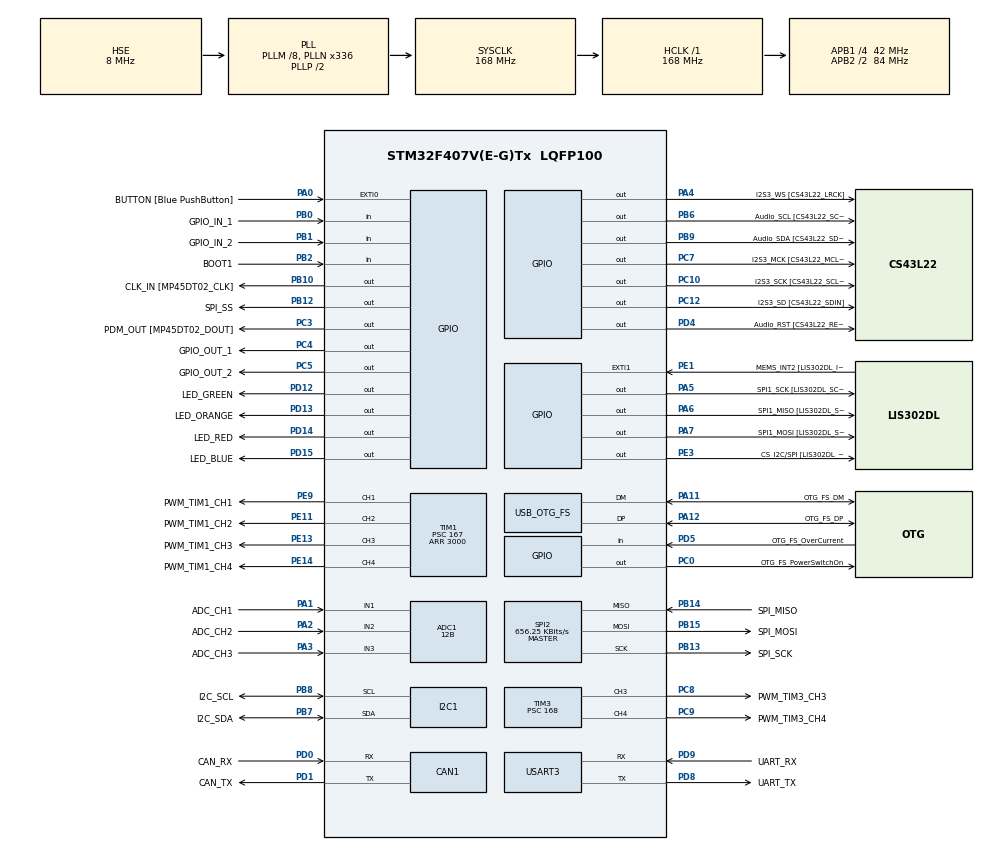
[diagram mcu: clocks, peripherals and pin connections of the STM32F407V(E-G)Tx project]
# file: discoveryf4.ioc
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ADC1.Channel-0\#ChannelRegularConversion=ADC_CHANNEL_1
ADC1.Channel-1\#ChannelRegularConversion=ADC_CHANNEL_2
ADC1.Channel-2\#ChannelRegularConversion=ADC_CHANNEL_3
ADC1.ClockPrescaler=ADC_CLOCK_SYNC_PCLK_DIV8
ADC1.ContinuousConvMode=ENABLE
ADC1.DMAContinuousRequests=ENABLE
ADC1.DataAlign=ADC_DATAALIGN_RIGHT
ADC1.DiscontinuousConvMode=DISABLE
ADC1.EOCSelection=ADC_EOC_SINGLE_CONV
ADC1.EnableAnalogWatchDog=false
ADC1.ExternalTrigConvEdge=ADC_EXTERNALTRIGCONVEDGE_NONE
ADC1.InjNumberOfConversion=0
ADC1.NbrOfConversion=3
ADC1.NbrOfConversionFlag=1
ADC1.Rank-0\#ChannelRegularConversion=1
ADC1.Rank-1\#ChannelRegularConversion=2
ADC1.Rank-2\#ChannelRegularConversion=3
ADC1.Resolution=ADC_RESOLUTION_12B
ADC1.SamplingTime-0\#ChannelRegularConversion=ADC_SAMPLETIME_480CYCLES
ADC1.SamplingTime-1\#ChannelRegularConversion=ADC_SAMPLETIME_480CYCLES
ADC1.SamplingTime-2\#ChannelRegularConversion=ADC_SAMPLETIME_480CYCLES
ADC1.ScanConvMode=ENABLE
ADC1.master=1
CAN1.BS1=CAN_BS1_1TQ
CAN1.BS2=CAN_BS2_1TQ
CAN1.CalculateTimeBit=1142
CAN1.CalculateTimeQuantum=380.95238095238096
Dma.ADC1.0.Channel=DMA_CHANNEL_0
Dma.ADC1.0.Direction=DMA_PERIPH_TO_MEMORY
Dma.ADC1.0.FIFOMode=DMA_FIFOMODE_DISABLE
Dma.ADC1.0.Instance=DMA2_Stream0
Dma.ADC1.0.MemDataAlignment=DMA_MDATAALIGN_HALFWORD
Dma.ADC1.0.MemInc=DMA_MINC_ENABLE
Dma.ADC1.0.Mode=DMA_CIRCULAR
Dma.ADC1.0.PeriphDataAlignment=DMA_PDATAALIGN_HALFWORD
Dma.ADC1.0.PeriphInc=DMA_PINC_DISABLE
Dma.ADC1.0.Priority=DMA_PRIORITY_LOW
Dma.Request0=ADC1
I2C1.I2C_Mode=I2C_Fast
Mcu.Family=STM32F4
Mcu.Name=STM32F407V(E-G)Tx
Mcu.Package=LQFP100
NVIC.ADC_IRQn=true\:0\:0\:false\:false\:true
NVIC.DMA2_Stream0_IRQn=true\:0\:0\:false\:false\:true
NVIC.I2C1_ER_IRQn=true\:0\:0\:false\:false\:true
NVIC.I2C1_EV_IRQn=true\:0\:0\:false\:false\:true
NVIC.OTG_FS_IRQn=true\:0\:0\:false\:false\:true
NVIC.PriorityGroup=NVIC_PRIORITYGROUP_0
NVIC.SPI2_IRQn=true\:0\:0\:false\:false\:true
NVIC.USART3_IRQn=true\:0\:0\:false\:false\:true
PA0-WKUP.GPIO_Label=BUTTON [Blue PushButton]
PA0-WKUP.GPIO_ModeDefaultEXTI=GPIO_MODE_EVT_RISING
PA0-WKUP.GPIO_PuPd=GPIO_NOPULL
PA0-WKUP.Signal=GPXTI0
PA1.GPIO_Label=ADC_CH1
PA1.Signal=ADCx_IN1
PA10.GPIO_Label=OTG_FS_ID
PA10.GPIO_Mode=GPIO_MODE_AF_PP
PA10.GPIO_PuPd=GPIO_NOPULL
PA10.GPIO_Speed=GPIO_SPEED_FREQ_LOW
PA10.Signal=USB_OTG_FS_ID
PA11.GPIO_Label=OTG_FS_DM
PA11.GPIO_Mode=GPIO_MODE_AF_PP
PA11.GPIO_PuPd=GPIO_NOPULL
PA11.GPIO_Speed=GPIO_SPEED_FREQ_LOW
PA11.Mode=Device_Only
PA11.Signal=USB_OTG_FS_DM
PA12.GPIO_Label=OTG_FS_DP
PA12.GPIO_Mode=GPIO_MODE_AF_PP
PA12.GPIO_PuPd=GPIO_NOPULL
PA12.GPIO_Speed=GPIO_SPEED_FREQ_LOW
PA12.Mode=Device_Only
PA12.Signal=USB_OTG_FS_DP
PA13.GPIO_Label=SWDIO
PA13.Mode=Trace-Asynchronous_SW
PA13.Signal=SYS_JTMS-SWDIO
PA14.GPIO_Label=SWCLK
PA14.Mode=Trace-Asynchronous_SW
PA14.Signal=SYS_JTCK-SWCLK
PA2.GPIO_Label=ADC_CH2
PA2.Signal=ADCx_IN2
PA3.GPIO_Label=ADC_CH3
PA3.Signal=ADCx_IN3
PA4.GPIO_Label=I2S3_WS [CS43L22_LRCK]
PA4.Signal=GPIO_Output
PA5.GPIO_Label=SPI1_SCK [LIS302DL_SCL/SPC]
PA5.Signal=GPIO_Output
PA6.GPIO_Label=SPI1_MISO [LIS302DL_SDO]
PA6.Signal=GPIO_Output
PA7.GPIO_Label=SPI1_MOSI [LIS302DL_SDA/SDI/SDO]
PA7.Signal=GPIO_Output
PA9.GPIO_Label=VBUS_FS
PA9.GPIO_Mode=GPIO_MODE_INPUT
PA9.GPIO_PuPd=GPIO_NOPULL
PA9.Signal=USB_OTG_FS_VBUS
PB0.GPIO_Label=GPIO_IN_1
PB0.Signal=GPIO_Input
PB1.GPIO_Label=GPIO_IN_2
PB1.Signal=GPIO_Input
PB10.GPIO_Label=CLK_IN [MP45DT02_CLK]
PB10.Signal=GPIO_Output
PB12.GPIO_Label=SPI_SS
PB12.Signal=GPIO_Output
PB13.GPIO_Label=SPI_SCK
PB13.Mode=Full_Duplex_Master
PB13.Signal=SPI2_SCK
PB14.GPIO_Label=SPI_MISO
PB14.Mode=Full_Duplex_Master
PB14.Signal=SPI2_MISO
PB15.GPIO_Label=SPI_MOSI
PB15.Mode=Full_Duplex_Master
PB15.Signal=SPI2_MOSI
PB2.GPIO_Label=BOOT1
PB2.GPIO_Mode=GPIO_MODE_INPUT
PB2.GPIO_PuPd=GPIO_NOPULL
PB2.Signal=GPIO_Input
PB3.GPIO_Label=SWO
PB3.Mode=Trace-Asynchronous_SW
PB3.Signal=SYS_JTDO-SWO
PB6.GPIO_Label=Audio_SCL [CS43L22_SCL]
PB6.Signal=GPIO_Output
PB7.GPIO_Label=I2C_SDA
PB7.Mode=I2C
PB7.Signal=I2C1_SDA
PB8.GPIO_Label=I2C_SCL
PB8.Mode=I2C
PB8.Signal=I2C1_SCL
PB9.GPIO_Label=Audio_SDA [CS43L22_SDA]
PB9.Signal=GPIO_Output
PC0.GPIO_Label=OTG_FS_PowerSwitchOn
PC0.GPIO_PuPd=GPIO_NOPULL
PC0.GPIO_Speed=GPIO_SPEED_FREQ_LOW
PC0.Signal=GPIO_Output
PC10.GPIO_Label=I2S3_SCK [CS43L22_SCLK]
PC10.Signal=GPIO_Output
PC12.GPIO_Label=I2S3_SD [CS43L22_SDIN]
PC12.Signal=GPIO_Output
PC14-OSC32_IN.GPIO_Label=PC14-OSC32_IN
PC14-OSC32_IN.Signal=RCC_OSC32_IN
PC15-OSC32_OUT.GPIO_Label=PC15-OSC32_OUT
PC15-OSC32_OUT.Signal=RCC_OSC32_OUT
PC3.GPIO_Label=PDM_OUT [MP45DT02_DOUT]
PC3.Signal=GPIO_Output
PC4.GPIO_Label=GPIO_OUT_1
PC4.Signal=GPIO_Output
PC5.GPIO_Label=GPIO_OUT_2
PC5.Signal=GPIO_Output
PC7.GPIO_Label=I2S3_MCK [CS43L22_MCLK]
PC7.Signal=GPIO_Output
PC8.GPIO_Label=PWM_TIM3_CH3
PC8.Signal=S_TIM3_CH3
PC9.GPIO_Label=PWM_TIM3_CH4
PC9.Signal=S_TIM3_CH4
PD0.GPIO_Label=CAN_RX
PD0.Mode=Master
PD0.Signal=CAN1_RX
PD1.GPIO_Label=CAN_TX
PD1.Mode=Master
PD1.Signal=CAN1_TX
PD12.GPIO_Label=LED_GREEN
PD12.GPIO_PuPd=GPIO_NOPULL
PD12.GPIO_Speed=GPIO_SPEED_FREQ_LOW
PD12.Signal=GPIO_Output
PD13.GPIO_Label=LED_ORANGE
PD13.GPIO_PuPd=GPIO_NOPULL
PD13.GPIO_Speed=GPIO_SPEED_FREQ_LOW
PD13.Signal=GPIO_Output
PD14.GPIO_Label=LED_RED
PD14.GPIO_PuPd=GPIO_NOPULL
PD14.GPIO_Speed=GPIO_SPEED_FREQ_LOW
PD14.Signal=GPIO_Output
PD15.GPIO_Label=LED_BLUE
PD15.GPIO_PuPd=GPIO_NOPULL
PD15.GPIO_Speed=GPIO_SPEED_FREQ_LOW
PD15.Signal=GPIO_Output
PD4.GPIO_Label=Audio_RST [CS43L22_RESET]
PD4.GPIO_PuPd=GPIO_NOPULL
PD4.GPIO_Speed=GPIO_SPEED_FREQ_LOW
PD4.Signal=GPIO_Output
PD5.GPIO_Label=OTG_FS_OverCurrent
PD5.GPIO_Mode=GPIO_MODE_INPUT
PD5.GPIO_PuPd=GPIO_NOPULL
PD5.Signal=GPIO_Input
PD8.GPIO_Label=UART_TX
PD8.Mode=Asynchronous
PD8.Signal=USART3_TX
PD9.GPIO_Label=UART_RX
PD9.Mode=Asynchronous
PD9.Signal=USART3_RX
PE1.GPIO_Label=MEMS_INT2 [LIS302DL_INT2]
PE1.GPIO_ModeDefaultEXTI=GPIO_MODE_EVT_RISING
PE1.GPIO_PuPd=GPIO_NOPULL
PE1.Signal=GPXTI1
PE11.GPIO_Label=PWM_TIM1_CH2
PE11.Signal=S_TIM1_CH2
PE13.GPIO_Label=PWM_TIM1_CH3
PE13.Signal=S_TIM1_CH3
PE14.GPIO_Label=PWM_TIM1_CH4
PE14.Signal=S_TIM1_CH4
PE3.GPIO_Label=CS_I2C/SPI [LIS302DL_CS_I2C/SPI]
PE3.GPIO_PuPd=GPIO_NOPULL
PE3.GPIO_Speed=GPIO_SPEED_FREQ_LOW
PE3.Signal=GPIO_Output
PE9.GPIO_Label=PWM_TIM1_CH1
PE9.Signal=S_TIM1_CH1
PH0-OSC_IN.GPIO_Label=PH0-OSC_IN
PH0-OSC_IN.Mode=HSE-External-Oscillator
PH0-OSC_IN.Signal=RCC_OSC_IN
PH1-OSC_OUT.GPIO_Label=PH1-OSC_OUT
PH1-OSC_OUT.Mode=HSE-External-Oscillator
PH1-OSC_OUT.Signal=RCC_OSC_OUT
ProjectManager.HeapSize=0x200
ProjectManager.StackSize=0x400
ProjectManager.TargetToolchain=SW4STM32
RCC.48MHZClocksFreq_Value=48000000
RCC.AHBFreq_Value=168000000
RCC.APB1CLKDivider=RCC_HCLK_DIV4
RCC.APB1Freq_Value=42000000
RCC.APB1TimFreq_Value=84000000
RCC.APB2CLKDivider=RCC_HCLK_DIV2
RCC.APB2Freq_Value=84000000
RCC.APB2TimFreq_Value=168000000
RCC.CortexFreq_Value=168000000
RCC.HCLKFreq_Value=168000000
RCC.HSE_VALUE=8000000
RCC.HSI_VALUE=16000000
RCC.LSE_VALUE=32768
RCC.PLLM=8
RCC.PLLN=336
RCC.PLLQ=7
RCC.SYSCLKFreq_VALUE=168000000
RCC.SYSCLKSource=RCC_SYSCLKSOURCE_PLLCLK
RCC.VCOOutputFreq_Value=336000000
SH.ADCx_IN1.0=ADC1_IN1,IN1
SH.ADCx_IN2.0=ADC1_IN2,IN2
SH.ADCx_IN3.0=ADC1_IN3,IN3
SH.S_TIM1_CH1.0=TIM1_CH1,PWM Generation1 CH1
SH.S_TIM1_CH2.0=TIM1_CH2,PWM Generation2 CH2
SH.S_TIM1_CH3.0=TIM1_CH3,PWM Generation3 CH3
SH.S_TIM1_CH4.0=TIM1_CH4,PWM Generation4 CH4
SH.S_TIM3_CH3.0=TIM3_CH3,PWM Generation3 CH3
SH.S_TIM3_CH4.0=TIM3_CH4,PWM Generation4 CH4
SPI2.BaudRatePrescaler=SPI_BAUDRATEPRESCALER_64
SPI2.CLKPhase=SPI_PHASE_2EDGE
SPI2.CLKPolarity=SPI_POLARITY_HIGH
SPI2.CalculateBaudRate=656.25 KBits/s
SPI2.Mode=SPI_MODE_MASTER
TIM1.Channel-PWM\ Generation2\ CH2=TIM_CHANNEL_2
TIM1.Channel-PWM\ Generation3\ CH3=TIM_CHANNEL_3
TIM1.Channel-PWM\ Generation4\ CH4=TIM_CHANNEL_4
TIM1.Period=3000
TIM1.Prescaler=167
TIM3.Channel-PWM\ Generation3\ CH3=TIM_CHANNEL_3
TIM3.Channel-PWM\ Generation4\ CH4=TIM_CHANNEL_4
TIM3.Period=50000
TIM3.Prescaler=168
TIM5.Period=4294967295
TIM5.Prescaler=83
USB_DEVICE.CLASS_NAME-CDC_FS=CDC
USB_DEVICE.CLASS_NAME_FS=CDC
USB_DEVICE.USBD_HandleTypeDef-CDC_FS=hUsbDeviceFS
USB_DEVICE.USBD_SUPPORT_USER_STRING-CDC_FS=1
USB_DEVICE.VirtualMode-CDC_FS=Cdc
USB_DEVICE.VirtualModeFS=Cdc_FS
USB_OTG_FS.VirtualMode=Device_Only
VP_TIM1_VS_ClockSourceINT.Mode=Internal
VP_TIM5_VS_ClockSourceINT.Mode=Internal
VP_TIM5_VS_no_output1.Mode=Output Compare1 No Output
VP_USB_DEVICE_VS_USB_DEVICE_CDC_FS.Mode=CDC_FS
board=STM32F4DISCOVERY

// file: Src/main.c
/**
  ******************************************************************************
  * File Name          : main.c
  * Description        : Main program body
  ******************************************************************************
  *
  * COPYRIGHT(c) 2016 STMicroelectronics
  *
  * Redistribution and use in source and binary forms, with or without modification,
  * are permitted provided that the following conditions are met:
  *   1. Redistributions of source code must retain the above copyright notice,
  *      this list of conditions and the following disclaimer.
  *   2. Redistributions in binary form must reproduce the above copyright notice,
  *      this list of conditions and the following disclaimer in the documentation
  *      and/or other materials provided with the distribution.
  *   3. Neither the name of STMicroelectronics nor the names of its contributors
  *      may be used to endorse or promote products derived from this software
  *      without specific prior written permission.
  *
  * THIS SOFTWARE IS PROVIDED BY THE COPYRIGHT HOLDERS AND CONTRIBUTORS "AS IS"
  * AND ANY EXPRESS OR IMPLIED WARRANTIES, INCLUDING, BUT NOT LIMITED TO, THE
  * IMPLIED WARRANTIES OF MERCHANTABILITY AND FITNESS FOR A PARTICULAR PURPOSE ARE
  * DISCLAIMED. IN NO EVENT SHALL THE COPYRIGHT HOLDER OR CONTRIBUTORS BE LIABLE
  * FOR ANY DIRECT, INDIRECT, INCIDENTAL, SPECIAL, EXEMPLARY, OR CONSEQUENTIAL
  * DAMAGES (INCLUDING, BUT NOT LIMITED TO, PROCUREMENT OF SUBSTITUTE GOODS OR
  * SERVICES; LOSS OF USE, DATA, OR PROFITS; OR BUSINESS INTERRUPTION) HOWEVER
  * CAUSED AND ON ANY THEORY OF LIABILITY, WHETHER IN CONTRACT, STRICT LIABILITY,
  * OR TORT (INCLUDING NEGLIGENCE OR OTHERWISE) ARISING IN ANY WAY OUT OF THE USE
  * OF THIS SOFTWARE, EVEN IF ADVISED OF THE POSSIBILITY OF SUCH DAMAGE.
  *
  ******************************************************************************
  */
#include "stm32f4xx_hal.h"
#include "adc.h"
#include "can.h"
#include "dma.h"
#include "i2c.h"
#include "spi.h"
#include "tim.h"
#include "usart.h"
#include "usb_device.h"
#include "gpio.h"

/* USER CODE BEGIN Includes */
#include "core/core.h"
/* USER CODE END Includes */

/* USER CODE BEGIN PV */
/* Private variables ---------------------------------------------------------*/

/* USER CODE END PV */

void SystemClock_Config(void);

/* USER CODE BEGIN PFP */
/* Private function prototypes -----------------------------------------------*/

/* USER CODE END PFP */

int main(void)
{

  /* MCU Configuration----------------------------------------------------------*/

  /* Reset of all peripherals, Initializes the Flash interface and the Systick. */
  HAL_Init();

  /* Configure the system clock */
  SystemClock_Config();

  /* Initialize all configured peripherals */
  MX_GPIO_Init();
  MX_DMA_Init();
  MX_ADC1_Init();
  MX_CAN1_Init();
  MX_I2C1_Init();
  MX_SPI2_Init();
  MX_TIM1_Init();
  MX_TIM3_Init();
  MX_USART3_UART_Init();
  MX_USB_DEVICE_Init();
  MX_TIM5_Init();

  /* USER CODE BEGIN 2 */
  core_setup();
  /* USER CODE END 2 */

  /* Infinite loop */
  while (1)
  {

  /* USER CODE BEGIN 3 */
  core_loop();
  }
  /* USER CODE END 3 */

}

/** System Clock Configuration
*/
void SystemClock_Config(void)
{

  RCC_OscInitTypeDef RCC_OscInitStruct;
  RCC_ClkInitTypeDef RCC_ClkInitStruct;

  __HAL_RCC_PWR_CLK_ENABLE();

  __HAL_PWR_VOLTAGESCALING_CONFIG(PWR_REGULATOR_VOLTAGE_SCALE1);

  RCC_OscInitStruct.OscillatorType = RCC_OSCILLATORTYPE_HSE;
  RCC_OscInitStruct.HSEState = RCC_HSE_ON;
  RCC_OscInitStruct.PLL.PLLState = RCC_PLL_ON;
  RCC_OscInitStruct.PLL.PLLSource = RCC_PLLSOURCE_HSE;
  RCC_OscInitStruct.PLL.PLLM = 8;
  RCC_OscInitStruct.PLL.PLLN = 336;
  RCC_OscInitStruct.PLL.PLLP = RCC_PLLP_DIV2;
  RCC_OscInitStruct.PLL.PLLQ = 7;
  HAL_RCC_OscConfig(&RCC_OscInitStruct);

  RCC_ClkInitStruct.ClockType = RCC_CLOCKTYPE_HCLK|RCC_CLOCKTYPE_SYSCLK
                              |RCC_CLOCKTYPE_PCLK1|RCC_CLOCKTYPE_PCLK2;
  RCC_ClkInitStruct.SYSCLKSource = RCC_SYSCLKSOURCE_PLLCLK;
  RCC_ClkInitStruct.AHBCLKDivider = RCC_SYSCLK_DIV1;
  RCC_ClkInitStruct.APB1CLKDivider = RCC_HCLK_DIV4;
  RCC_ClkInitStruct.APB2CLKDivider = RCC_HCLK_DIV2;
  HAL_RCC_ClockConfig(&RCC_ClkInitStruct, FLASH_LATENCY_5);

  HAL_SYSTICK_Config(HAL_RCC_GetHCLKFreq()/1000);

  HAL_SYSTICK_CLKSourceConfig(SYSTICK_CLKSOURCE_HCLK);

  /* SysTick_IRQn interrupt configuration */
  HAL_NVIC_SetPriority(SysTick_IRQn, 0, 0);
}

/************************ (C) COPYRIGHT STMicroelectronics *****END OF FILE****/
